VERSION ""

NS_ :

BS_:

BU_:

BO_ 2364540422 Controller_system_station_1: 8 Vector__XXX
 SG_ motor_gear : 32|2@1+ (1,0) [0|3] "" Vector__XXX

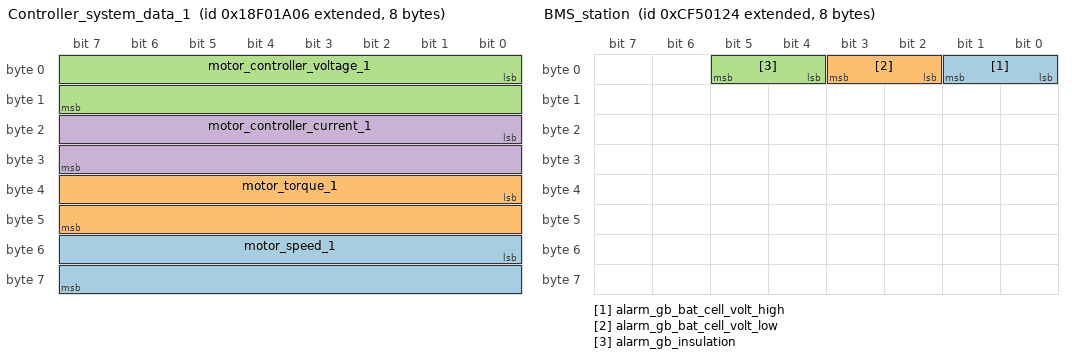
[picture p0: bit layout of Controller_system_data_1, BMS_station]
BO_ 2565872134 Controller_system_data_1: 8 Vector__XXX
 SG_ motor_speed_1 : 48|16@1+ (1,0) [0|11000] "rpm" Vector__XXX
 SG_ motor_torque_1 : 32|16@1+ (0.1,0) [0|600] "Nm" Vector__XXX
 SG_ motor_controller_voltage_1 : 0|16@1+ (0.1,0) [0|500] "V" Vector__XXX
 SG_ motor_controller_current_1 : 16|16@1+ (0.1,-320) [-320|600] "A" Vector__XXX

BO_ 2565878790 Controller_system_data_2: 8 Vector__XXX
 SG_ motor_controller_temp_1 : 48|8@1+ (1,-40) [-40|150] "¡æ" Vector__XXX
 SG_ motor_temp_1 : 56|8@1+ (1,-40) [-40|150] "¡æ" Vector__XXX

BO_ 2364866852 BMS_station: 8 Vector__XXX
 SG_ alarm_gb_bat_cell_volt_high : 0|2@1+ (1,0) [0|2] "" Vector__XXX
 SG_ alarm_gb_bat_cell_volt_low : 2|2@1+ (1,0) [0|2] "" Vector__XXX
 SG_ alarm_gb_insulation : 4|2@1+ (1,0) [0|2] "" Vector__XXX

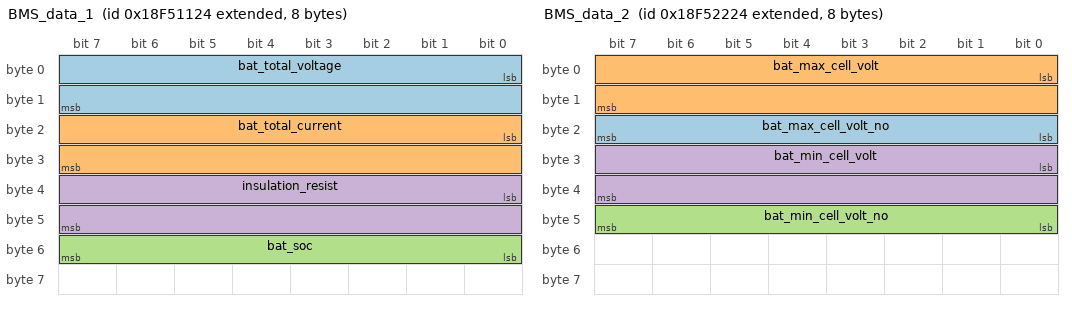
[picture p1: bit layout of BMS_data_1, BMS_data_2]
BO_ 2566197540 BMS_data_1: 8 Vector__XXX
 SG_ bat_total_voltage : 0|16@1+ (0.1,0) [0|500] "V" Vector__XXX
 SG_ bat_total_current : 16|16@1+ (0.1,-320) [-320|400] "A" Vector__XXX
 SG_ bat_soc : 48|8@1+ (1,0) [0|100] "%" Vector__XXX
 SG_ insulation_resist : 32|16@1+ (1,0) [0|30000] "K¦¸" Vector__XXX

BO_ 2566201892 BMS_data_2: 8 Vector__XXX
 SG_ bat_max_cell_volt_no : 16|8@1+ (1,0) [0|255] "" Vector__XXX
 SG_ bat_max_cell_volt : 0|16@1+ (0.001,0) [0|6] "V" Vector__XXX
 SG_ bat_min_cell_volt_no : 40|8@1+ (1,0) [0|255] "" Vector__XXX
 SG_ bat_min_cell_volt : 24|16@1+ (0.001,0) [0|6] "V" Vector__XXX

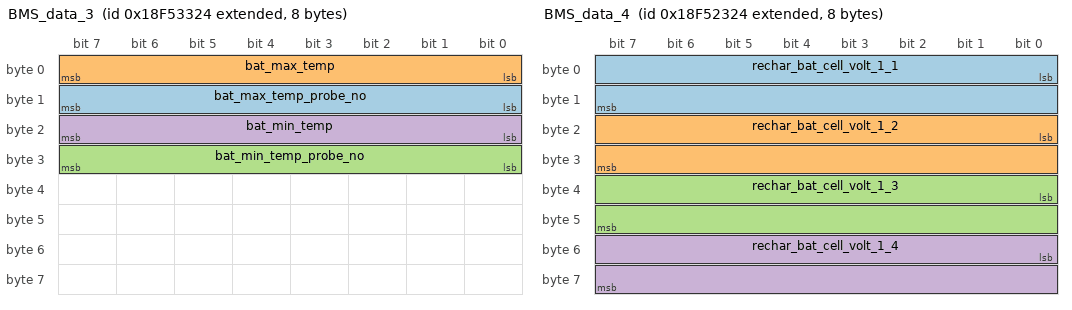
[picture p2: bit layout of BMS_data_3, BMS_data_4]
BO_ 2566206244 BMS_data_3: 8 Vector__XXX
 SG_ bat_max_temp_probe_no : 8|8@1+ (1,0) [0|255] "" Vector__XXX
 SG_ bat_max_temp : 0|8@1+ (1,-40) [-40|150] "¡æ" Vector__XXX
 SG_ bat_min_temp_probe_no : 24|8@1+ (1,0) [0|255] "" Vector__XXX
 SG_ bat_min_temp : 16|8@1+ (1,-40) [-40|150] "¡æ" Vector__XXX

BO_ 2566202148 BMS_data_4: 8 Vector__XXX
 SG_ rechar_bat_cell_volt_1_1 : 0|16@1+ (0.001,0) [0|6] "V" Vector__XXX
 SG_ rechar_bat_cell_volt_1_2 : 16|16@1+ (0.001,0) [0|6] "V" Vector__XXX
 SG_ rechar_bat_cell_volt_1_3 : 32|16@1+ (0.001,0) [0|6] "V" Vector__XXX
 SG_ rechar_bat_cell_volt_1_4 : 48|16@1+ (0.001,0) [0|6] "V" Vector__XXX

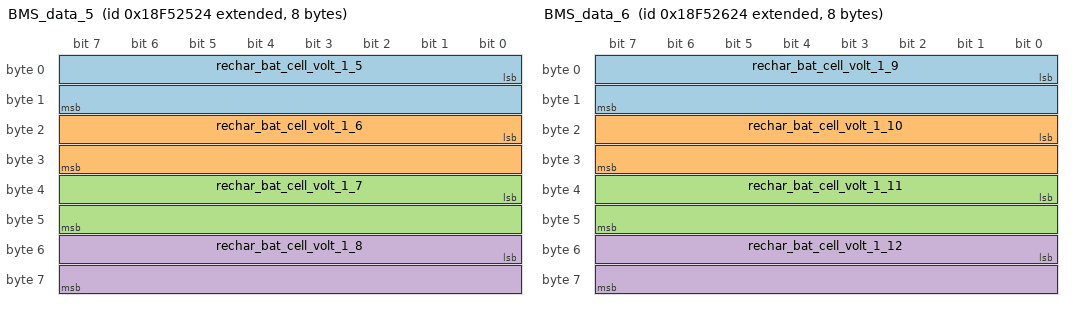
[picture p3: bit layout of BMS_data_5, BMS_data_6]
BO_ 2566202660 BMS_data_5: 8 Vector__XXX
 SG_ rechar_bat_cell_volt_1_5 : 0|16@1+ (0.001,0) [0|6] "V" Vector__XXX
 SG_ rechar_bat_cell_volt_1_6 : 16|16@1+ (0.001,0) [0|6] "V" Vector__XXX
 SG_ rechar_bat_cell_volt_1_7 : 32|16@1+ (0.001,0) [0|6] "V" Vector__XXX
 SG_ rechar_bat_cell_volt_1_8 : 48|16@1+ (0.001,0) [0|6] "V" Vector__XXX

BO_ 2566202916 BMS_data_6: 8 Vector__XXX
 SG_ rechar_bat_cell_volt_1_9 : 0|16@1+ (0.001,0) [0|6] "V" Vector__XXX
 SG_ rechar_bat_cell_volt_1_10 : 16|16@1+ (0.001,0) [0|6] "V" Vector__XXX
 SG_ rechar_bat_cell_volt_1_11 : 32|16@1+ (0.001,0) [0|6] "V" Vector__XXX
 SG_ rechar_bat_cell_volt_1_12 : 48|16@1+ (0.001,0) [0|6] "V" Vector__XXX

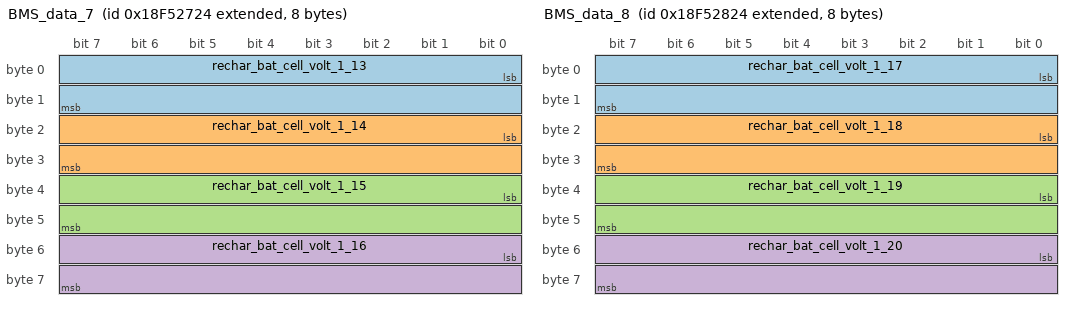
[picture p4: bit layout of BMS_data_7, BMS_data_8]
BO_ 2566203172 BMS_data_7: 8 Vector__XXX
 SG_ rechar_bat_cell_volt_1_13 : 0|16@1+ (0.001,0) [0|6] "V" Vector__XXX
 SG_ rechar_bat_cell_volt_1_14 : 16|16@1+ (0.001,0) [0|6] "V" Vector__XXX
 SG_ rechar_bat_cell_volt_1_15 : 32|16@1+ (0.001,0) [0|6] "V" Vector__XXX
 SG_ rechar_bat_cell_volt_1_16 : 48|16@1+ (0.001,0) [0|6] "V" Vector__XXX

BO_ 2566203428 BMS_data_8: 8 Vector__XXX
 SG_ rechar_bat_cell_volt_1_17 : 0|16@1+ (0.001,0) [0|6] "V" Vector__XXX
 SG_ rechar_bat_cell_volt_1_18 : 16|16@1+ (0.001,0) [0|6] "V" Vector__XXX
 SG_ rechar_bat_cell_volt_1_19 : 32|16@1+ (0.001,0) [0|6] "V" Vector__XXX
 SG_ rechar_bat_cell_volt_1_20 : 48|16@1+ (0.001,0) [0|6] "V" Vector__XXX

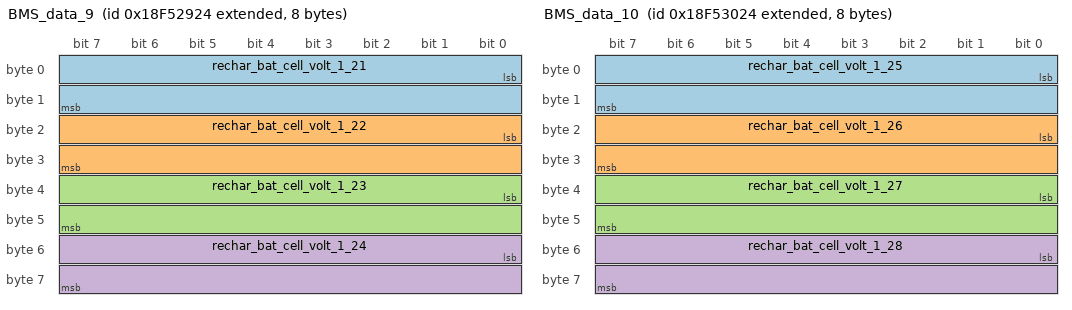
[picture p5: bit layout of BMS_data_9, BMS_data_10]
BO_ 2566203684 BMS_data_9: 8 Vector__XXX
 SG_ rechar_bat_cell_volt_1_21 : 0|16@1+ (0.001,0) [0|6] "V" Vector__XXX
 SG_ rechar_bat_cell_volt_1_22 : 16|16@1+ (0.001,0) [0|6] "V" Vector__XXX
 SG_ rechar_bat_cell_volt_1_23 : 32|16@1+ (0.001,0) [0|6] "V" Vector__XXX
 SG_ rechar_bat_cell_volt_1_24 : 48|16@1+ (0.001,0) [0|6] "V" Vector__XXX

BO_ 2566205476 BMS_data_10: 8 Vector__XXX
 SG_ rechar_bat_cell_volt_1_25 : 0|16@1+ (0.001,0) [0|6] "V" Vector__XXX
 SG_ rechar_bat_cell_volt_1_26 : 16|16@1+ (0.001,0) [0|6] "V" Vector__XXX
 SG_ rechar_bat_cell_volt_1_27 : 32|16@1+ (0.001,0) [0|6] "V" Vector__XXX
 SG_ rechar_bat_cell_volt_1_28 : 48|16@1+ (0.001,0) [0|6] "V" Vector__XXX

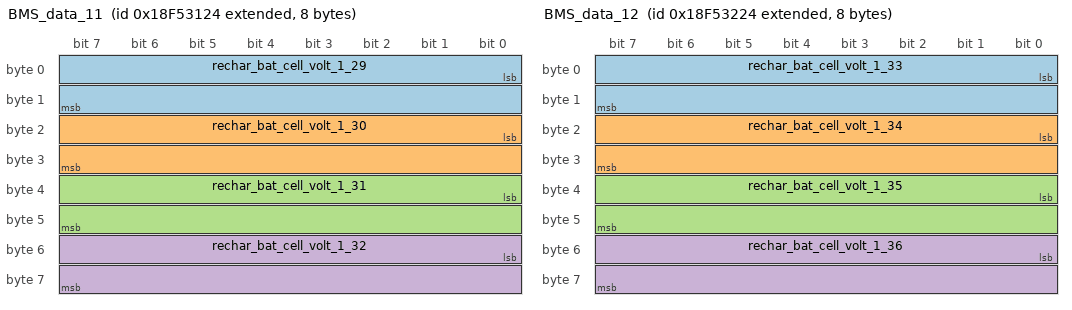
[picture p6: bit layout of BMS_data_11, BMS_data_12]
BO_ 2566205732 BMS_data_11: 8 Vector__XXX
 SG_ rechar_bat_cell_volt_1_29 : 0|16@1+ (0.001,0) [0|6] "V" Vector__XXX
 SG_ rechar_bat_cell_volt_1_30 : 16|16@1+ (0.001,0) [0|6] "V" Vector__XXX
 SG_ rechar_bat_cell_volt_1_31 : 32|16@1+ (0.001,0) [0|6] "V" Vector__XXX
 SG_ rechar_bat_cell_volt_1_32 : 48|16@1+ (0.001,0) [0|6] "V" Vector__XXX

BO_ 2566205988 BMS_data_12: 8 Vector__XXX
 SG_ rechar_bat_cell_volt_1_33 : 0|16@1+ (0.001,0) [0|6] "V" Vector__XXX
 SG_ rechar_bat_cell_volt_1_34 : 16|16@1+ (0.001,0) [0|6] "V" Vector__XXX
 SG_ rechar_bat_cell_volt_1_35 : 32|16@1+ (0.001,0) [0|6] "V" Vector__XXX
 SG_ rechar_bat_cell_volt_1_36 : 48|16@1+ (0.001,0) [0|6] "V" Vector__XXX

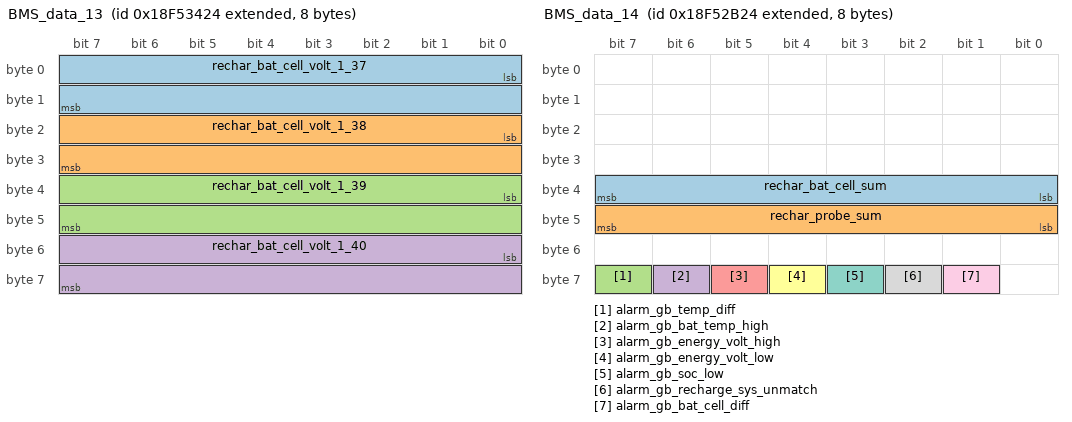
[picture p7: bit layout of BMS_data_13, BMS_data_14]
BO_ 2566206500 BMS_data_13: 8 Vector__XXX
 SG_ rechar_bat_cell_volt_1_37 : 0|16@1+ (0.001,0) [0|6] "V" Vector__XXX
 SG_ rechar_bat_cell_volt_1_38 : 16|16@1+ (0.001,0) [0|6] "V" Vector__XXX
 SG_ rechar_bat_cell_volt_1_39 : 32|16@1+ (0.001,0) [0|6] "V" Vector__XXX
 SG_ rechar_bat_cell_volt_1_40 : 48|16@1+ (0.001,0) [0|6] "V" Vector__XXX

BO_ 2566204196 BMS_data_14: 8 Vector__XXX
 SG_ rechar_bat_cell_sum : 32|8@1+ (1,0) [0|255] "" Vector__XXX
 SG_ rechar_probe_sum : 40|8@1+ (1,0) [0|255] "" Vector__XXX
 SG_ alarm_gb_temp_diff : 63|1@1+ (1,0) [0|1] "" Vector__XXX
 SG_ alarm_gb_bat_temp_high : 62|1@1+ (1,0) [0|1] "" Vector__XXX
 SG_ alarm_gb_energy_volt_high : 61|1@1+ (1,0) [0|1] "" Vector__XXX
 SG_ alarm_gb_energy_volt_low : 60|1@1+ (1,0) [0|1] "" Vector__XXX
 SG_ alarm_gb_soc_low : 59|1@1+ (1,0) [0|1] "" Vector__XXX
 SG_ alarm_gb_recharge_sys_unmatch : 58|1@1+ (1,0) [0|1] "" Vector__XXX
 SG_ alarm_gb_bat_cell_diff : 57|1@1+ (1,0) [0|1] "" Vector__XXX

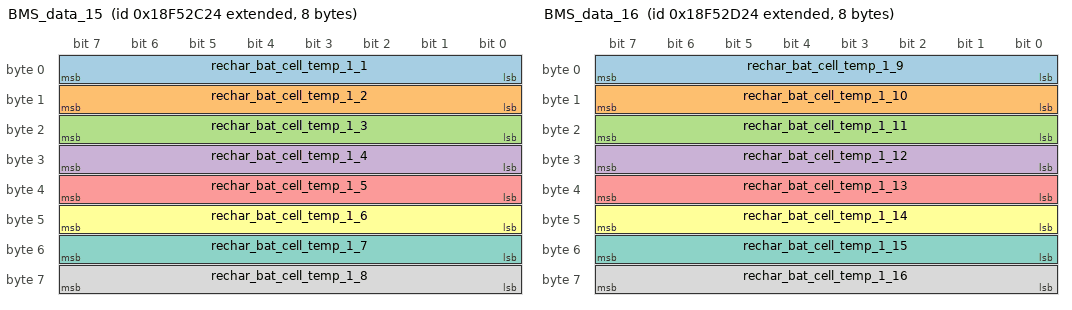
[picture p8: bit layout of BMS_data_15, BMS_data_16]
BO_ 2566204452 BMS_data_15: 8 Vector__XXX
 SG_ rechar_bat_cell_temp_1_1 : 0|8@1+ (1,-40) [-40|150] "¡æ" Vector__XXX
 SG_ rechar_bat_cell_temp_1_2 : 8|8@1+ (1,-40) [-40|150] "¡æ" Vector__XXX
 SG_ rechar_bat_cell_temp_1_3 : 16|8@1+ (1,-40) [-40|150] "¡æ" Vector__XXX
 SG_ rechar_bat_cell_temp_1_4 : 24|8@1+ (1,-40) [-40|150] "¡æ" Vector__XXX
 SG_ rechar_bat_cell_temp_1_5 : 32|8@1+ (1,-40) [-40|150] "¡æ" Vector__XXX
 SG_ rechar_bat_cell_temp_1_6 : 40|8@1+ (1,-40) [-40|150] "¡æ" Vector__XXX
 SG_ rechar_bat_cell_temp_1_7 : 48|8@1+ (1,-40) [-40|150] "¡æ" Vector__XXX
 SG_ rechar_bat_cell_temp_1_8 : 56|8@1+ (1,-40) [-40|150] "¡æ" Vector__XXX

BO_ 2566204708 BMS_data_16: 8 Vector__XXX
 SG_ rechar_bat_cell_temp_1_9 : 0|8@1+ (1,-40) [-40|150] "¡æ" Vector__XXX
 SG_ rechar_bat_cell_temp_1_10 : 8|8@1+ (1,-40) [-40|150] "¡æ" Vector__XXX
 SG_ rechar_bat_cell_temp_1_11 : 16|8@1+ (1,-40) [-40|150] "¡æ" Vector__XXX
 SG_ rechar_bat_cell_temp_1_12 : 24|8@1+ (1,-40) [-40|150] "¡æ" Vector__XXX
 SG_ rechar_bat_cell_temp_1_13 : 32|8@1+ (1,-40) [-40|150] "¡æ" Vector__XXX
 SG_ rechar_bat_cell_temp_1_14 : 40|8@1+ (1,-40) [-40|150] "¡æ" Vector__XXX
 SG_ rechar_bat_cell_temp_1_15 : 48|8@1+ (1,-40) [-40|150] "¡æ" Vector__XXX
 SG_ rechar_bat_cell_temp_1_16 : 56|8@1+ (1,-40) [-40|150] "¡æ" Vector__XXX

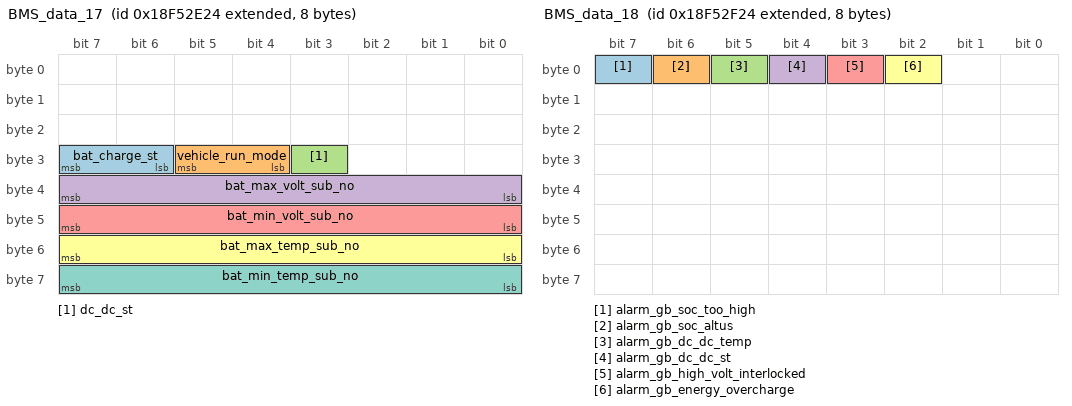
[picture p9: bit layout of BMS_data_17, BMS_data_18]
BO_ 2566204964 BMS_data_17: 8 Vector__XXX
 SG_ bat_charge_st : 30|2@1+ (1,0) [0|3] "" Vector__XXX
 SG_ vehicle_run_mode : 28|2@1+ (1,0) [0|3] "" Vector__XXX
 SG_ dc_dc_st : 27|1@1+ (1,0) [0|1] "" Vector__XXX
 SG_ bat_max_volt_sub_no : 32|8@1+ (1,0) [1|255] "" Vector__XXX
 SG_ bat_min_volt_sub_no : 40|8@1+ (1,0) [1|255] "" Vector__XXX
 SG_ bat_max_temp_sub_no : 48|8@1+ (1,0) [1|255] "" Vector__XXX
 SG_ bat_min_temp_sub_no : 56|8@1+ (1,0) [1|255] "" Vector__XXX

BO_ 2566205220 BMS_data_18: 8 Vector__XXX
 SG_ alarm_gb_soc_too_high : 7|1@1+ (1,0) [0|1] "" Vector__XXX
 SG_ alarm_gb_soc_altus : 6|1@1+ (1,0) [0|1] "" Vector__XXX
 SG_ alarm_gb_dc_dc_temp : 5|1@1+ (1,0) [0|1] "" Vector__XXX
 SG_ alarm_gb_dc_dc_st : 4|1@1+ (1,0) [0|1] "" Vector__XXX
 SG_ alarm_gb_high_volt_interlocked : 3|1@1+ (1,0) [0|1] "" Vector__XXX
 SG_ alarm_gb_energy_overcharge : 2|1@1+ (1,0) [0|1] "" Vector__XXX

BO_ 2566142231 Dashboard_data_1: 8 Vector__XXX
 SG_ vehicle_speed : 48|16@1+ (0.1,0) [0|200] "Km/h" Vector__XXX
 SG_ vehicle_mileage : 0|32@1+ (0.1,0) [0|429496729.5] "Km" Vector__XXX

BA_DEF_ BO_  "GenMsgSendType" ENUM  "cyclic","NotUsed","IfActive","NotUsed","NotUsed","NotUsed","NotUsed","NotUsed","noMsgSendType";
BA_DEF_ BO_  "GenMsgCycleTime" INT 0 3600000;
BA_DEF_  "DBName" STRING ;
BA_DEF_  "BusType" STRING ;
BA_DEF_ BO_  "VFrameFormat" ENUM  "StandardCAN","ExtendedCAN","reserved","J1939PG";
BA_DEF_DEF_  "GenMsgSendType" "noMsgSendType";
BA_DEF_DEF_  "GenMsgCycleTime" 0;
BA_DEF_DEF_  "DBName" "";
BA_DEF_DEF_  "BusType" "";
BA_DEF_DEF_  "VFrameFormat" "J1939PG";
BA_ "BusType" "CAN";
BA_ "DBName" "lingchen";
BA_ "GenMsgCycleTime" BO_ 2364540422 50;
BA_ "GenMsgSendType" BO_ 2364540422 0;
BA_ "GenMsgCycleTime" BO_ 2565872134 100;
BA_ "GenMsgSendType" BO_ 2565872134 0;
BA_ "GenMsgCycleTime" BO_ 2565878790 100;
BA_ "GenMsgSendType" BO_ 2565878790 0;
BA_ "GenMsgCycleTime" BO_ 2364866852 50;
BA_ "GenMsgSendType" BO_ 2364866852 0;
BA_ "GenMsgCycleTime" BO_ 2566197540 100;
BA_ "GenMsgSendType" BO_ 2566197540 0;
BA_ "GenMsgCycleTime" BO_ 2566201892 100;
BA_ "GenMsgSendType" BO_ 2566201892 0;
BA_ "GenMsgCycleTime" BO_ 2566206244 100;
BA_ "GenMsgSendType" BO_ 2566206244 0;
BA_ "GenMsgCycleTime" BO_ 2566202148 10000;
BA_ "GenMsgSendType" BO_ 2566202148 0;
BA_ "GenMsgCycleTime" BO_ 2566202660 10000;
BA_ "GenMsgSendType" BO_ 2566202660 0;
BA_ "GenMsgCycleTime" BO_ 2566202916 10000;
BA_ "GenMsgSendType" BO_ 2566202916 0;
BA_ "GenMsgCycleTime" BO_ 2566203172 10000;
BA_ "GenMsgSendType" BO_ 2566203172 0;
BA_ "GenMsgCycleTime" BO_ 2566203428 10000;
BA_ "GenMsgSendType" BO_ 2566203428 0;
BA_ "GenMsgCycleTime" BO_ 2566203684 10000;
BA_ "GenMsgSendType" BO_ 2566203684 0;
BA_ "GenMsgCycleTime" BO_ 2566205476 10000;
BA_ "GenMsgSendType" BO_ 2566205476 0;
BA_ "GenMsgCycleTime" BO_ 2566205732 10000;
BA_ "GenMsgSendType" BO_ 2566205732 0;
BA_ "GenMsgCycleTime" BO_ 2566205988 10000;
BA_ "GenMsgSendType" BO_ 2566205988 0;
BA_ "GenMsgCycleTime" BO_ 2566206500 10000;
BA_ "GenMsgSendType" BO_ 2566206500 0;
BA_ "GenMsgCycleTime" BO_ 2566204196 10000;
BA_ "GenMsgSendType" BO_ 2566204196 0;
BA_ "GenMsgCycleTime" BO_ 2566204452 10000;
BA_ "GenMsgSendType" BO_ 2566204452 0;
BA_ "GenMsgCycleTime" BO_ 2566204708 10000;
BA_ "GenMsgSendType" BO_ 2566204708 0;
BA_ "GenMsgCycleTime" BO_ 2566204964 10000;
BA_ "GenMsgSendType" BO_ 2566204964 0;
BA_ "GenMsgCycleTime" BO_ 2566205220 10000;
BA_ "GenMsgSendType" BO_ 2566205220 0;
BA_ "GenMsgCycleTime" BO_ 2566142231 100;
BA_ "GenMsgSendType" BO_ 2566142231 0;
VAL_ 2364540422 motor_gear 0 "N  ##0x00" 1 "R  ##0x0D" 2 "D  ##0x0E" 3 "P  ##0x0F" ;
VAL_ 2364866852 alarm_gb_bat_cell_volt_high 0 "Normal  ##level_0" 1 "Level_1 alarm of low voltage  ##level_1" 2 "Level_2 alarm alarm of low voltage  ##level_2" ;
VAL_ 2364866852 alarm_gb_bat_cell_volt_low 0 "Normal  ##level_0" 1 "Level_1 alarm of over voltage  ##level_1" 2 "Level_2 alarm alarm of over voltage  ##level_2" ;
VAL_ 2364866852 alarm_gb_insulation 0 "Normal  ##level_0" 1 "Level_1 alarm of Insulation  ##level_1" 2 "Level_2 alarm alarm of Insulation  ##level_2" ;
VAL_ 2566204196 alarm_gb_temp_diff 0 "Normal  ##level_0" 1 "Temperature difference alarm  ##level_1" ;
VAL_ 2566204196 alarm_gb_bat_temp_high 0 "Normal  ##level_0" 1 "Battery high temperature alarm  ##level_1" ;
VAL_ 2566204196 alarm_gb_energy_volt_high 0 "Normal  ##level_0" 1 "Battery high temperature alarm  ##level_1" ;
VAL_ 2566204196 alarm_gb_energy_volt_low 0 "Normal  ##level_0" 1 "Low voltage alarm of the on-board energy storage device  ##level_1" ;
VAL_ 2566204196 alarm_gb_soc_low 0 "Normal  ##level_0" 1 "SOC low alarm  ##level_1" ;
VAL_ 2566204196 alarm_gb_recharge_sys_unmatch 0 "Normal  ##level_0" 1 "Miss-matching alarm of chargeable energy storage system  ##level_1" ;
VAL_ 2566204196 alarm_gb_bat_cell_diff 0 "Normal  ##level_0" 1 "Consistency error alarm of single battery cell  ##level_1" ;
VAL_ 2566204964 bat_charge_st 0 "Invalid" 1 "Not charging ##0x03" 2 "Parking and charging  ##0x01" 3 "Charging complete ##0x04" ;
VAL_ 2566204964 vehicle_run_mode 0 "Invalid" 1 "Pure Electric ##0x01" 2 "Hybrid ##0x02" 3 "Fuel ##0x03" ;
VAL_ 2566204964 dc_dc_st 0 "Break #0x02" 1 "Work #0x01" ;
VAL_ 2566205220 alarm_gb_soc_too_high 0 "Normal  ##level_0" 1 "SOC high alarm  ##level_1" ;
VAL_ 2566205220 alarm_gb_soc_altus 0 "Normal   ##level_0" 1 "SOC jump alarm  ##level_1" ;
VAL_ 2566205220 alarm_gb_dc_dc_temp 0 "Normal  ##level_0" 1 "DC temperature alarm   ##level_1" ;
VAL_ 2566205220 alarm_gb_dc_dc_st 0 "Normal  ##level_0" 1 "DC-DC status alarm  ##level_1" ;
VAL_ 2566205220 alarm_gb_high_volt_interlocked 0 "Normal  ##level_0" 1 "High voltage inter-lock status alarm   ##level_1" ;
VAL_ 2566205220 alarm_gb_energy_overcharge 0 "Normal  ##level_0" 1 "Over charge alarm of the on-board energy storage device  ##level_1" ;
